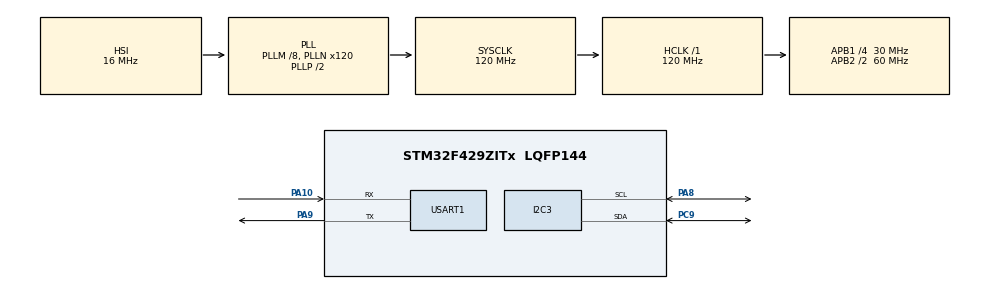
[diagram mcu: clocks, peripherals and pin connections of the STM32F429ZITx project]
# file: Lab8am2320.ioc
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Mcu.Family=STM32F4
Mcu.Name=STM32F429ZITx
Mcu.Package=LQFP144
NVIC.PriorityGroup=NVIC_PRIORITYGROUP_4
PA10.Mode=Asynchronous
PA10.Signal=USART1_RX
PA8.Mode=I2C
PA8.Signal=I2C3_SCL
PA9.Mode=Asynchronous
PA9.Signal=USART1_TX
PC9.Mode=I2C
PC9.Signal=I2C3_SDA
ProjectManager.HeapSize=0x200
ProjectManager.StackSize=0x400
ProjectManager.TargetToolchain=STM32CubeIDE
RCC.48MHZClocksFreq_Value=60000000
RCC.AHBFreq_Value=120000000
RCC.APB1CLKDivider=RCC_HCLK_DIV4
RCC.APB1Freq_Value=30000000
RCC.APB1TimFreq_Value=60000000
RCC.APB2CLKDivider=RCC_HCLK_DIV2
RCC.APB2Freq_Value=60000000
RCC.APB2TimFreq_Value=120000000
RCC.CortexFreq_Value=120000000
RCC.HCLKFreq_Value=120000000
RCC.HSE_VALUE=25000000
RCC.HSI_VALUE=16000000
RCC.LSE_VALUE=32768
RCC.PLLM=8
RCC.PLLN=120
RCC.SYSCLKFreq_VALUE=120000000
RCC.SYSCLKSource=RCC_SYSCLKSOURCE_PLLCLK
RCC.VCOOutputFreq_Value=240000000
USART1.VirtualMode=VM_ASYNC
board=custom

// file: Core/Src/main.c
/* USER CODE BEGIN Header */
/**
  ******************************************************************************
  * @file           : main.c
  * @brief          : Main program body
  ******************************************************************************
  * @attention
  *
  * <h2><center>&copy; Copyright (c) 2021 STMicroelectronics.
  * All rights reserved.</center></h2>
  *
  * This software component is licensed by ST under BSD 3-Clause license,
  * the "License"; You may not use this file except in compliance with the
  * License. You may obtain a copy of the License at:
  *                        opensource.org/licenses/BSD-3-Clause
  *
  ******************************************************************************
  */
/* USER CODE END Header */
#include "main.h"

/* USER CODE BEGIN Includes */
#include "am2320.h"
#include "string.h"
/* USER CODE END Includes */

I2C_HandleTypeDef hi2c3;

UART_HandleTypeDef huart1;

void SystemClock_Config(void);
static void MX_GPIO_Init(void);
static void MX_I2C3_Init(void);
static void MX_USART1_UART_Init(void);

int main(void)
{

  /* MCU Configuration--------------------------------------------------------*/

  /* Reset of all peripherals, Initializes the Flash interface and the Systick. */
  HAL_Init();

  /* Configure the system clock */
  SystemClock_Config();

  /* Initialize all configured peripherals */
  MX_GPIO_Init();
  MX_I2C3_Init();
  MX_USART1_UART_Init();
  /* USER CODE BEGIN 2 */
  Am2320_HandleTypeDef Am2320_;
  Am2320_ = am2320_Init(&hi2c3, 0x5C << 1);
  float temperature, humidity;
  char str[50];
  /* USER CODE END 2 */

  /* Infinite loop */
  while (1)
  {

    /* USER CODE BEGIN 3 */
	  am2320_GetTemperatureAndHumidity(&Am2320_, &temperature, &humidity);
	  uint8_t* sentTemp;
	  uint8_t sentHumid;
	  sprintf(str, "Temperature = %4.1f\tHumidity = %4.1f\n\r", temperature, humidity);
	  	  while(__HAL_UART_GET_FLAG(&huart1,UART_FLAG_TC)==RESET){}
	  	  HAL_UART_Transmit(&huart1, (uint8_t*) str, strlen(str), 200);
	    HAL_Delay(3000);
  }
  /* USER CODE END 3 */
}

void SystemClock_Config(void)
{
  RCC_OscInitTypeDef RCC_OscInitStruct = {0};
  RCC_ClkInitTypeDef RCC_ClkInitStruct = {0};

  /** Configure the main internal regulator output voltage
  */
  __HAL_RCC_PWR_CLK_ENABLE();
  __HAL_PWR_VOLTAGESCALING_CONFIG(PWR_REGULATOR_VOLTAGE_SCALE3);
  /** Initializes the RCC Oscillators according to the specified parameters
  * in the RCC_OscInitTypeDef structure.
  */
  RCC_OscInitStruct.OscillatorType = RCC_OSCILLATORTYPE_HSI;
  RCC_OscInitStruct.HSIState = RCC_HSI_ON;
  RCC_OscInitStruct.HSICalibrationValue = RCC_HSICALIBRATION_DEFAULT;
  RCC_OscInitStruct.PLL.PLLState = RCC_PLL_ON;
  RCC_OscInitStruct.PLL.PLLSource = RCC_PLLSOURCE_HSI;
  RCC_OscInitStruct.PLL.PLLM = 8;
  RCC_OscInitStruct.PLL.PLLN = 120;
  RCC_OscInitStruct.PLL.PLLP = RCC_PLLP_DIV2;
  RCC_OscInitStruct.PLL.PLLQ = 4;
  if (HAL_RCC_OscConfig(&RCC_OscInitStruct) != HAL_OK)
  {
    Error_Handler();
  }
  /** Initializes the CPU, AHB and APB buses clocks
  */
  RCC_ClkInitStruct.ClockType = RCC_CLOCKTYPE_HCLK|RCC_CLOCKTYPE_SYSCLK
                              |RCC_CLOCKTYPE_PCLK1|RCC_CLOCKTYPE_PCLK2;
  RCC_ClkInitStruct.SYSCLKSource = RCC_SYSCLKSOURCE_PLLCLK;
  RCC_ClkInitStruct.AHBCLKDivider = RCC_SYSCLK_DIV1;
  RCC_ClkInitStruct.APB1CLKDivider = RCC_HCLK_DIV4;
  RCC_ClkInitStruct.APB2CLKDivider = RCC_HCLK_DIV2;

  if (HAL_RCC_ClockConfig(&RCC_ClkInitStruct, FLASH_LATENCY_3) != HAL_OK)
  {
    Error_Handler();
  }
}

static void MX_I2C3_Init(void)
{

  hi2c3.Instance = I2C3;
  hi2c3.Init.ClockSpeed = 100000;
  hi2c3.Init.DutyCycle = I2C_DUTYCYCLE_2;
  hi2c3.Init.OwnAddress1 = 0;
  hi2c3.Init.AddressingMode = I2C_ADDRESSINGMODE_7BIT;
  hi2c3.Init.DualAddressMode = I2C_DUALADDRESS_DISABLE;
  hi2c3.Init.OwnAddress2 = 0;
  hi2c3.Init.GeneralCallMode = I2C_GENERALCALL_DISABLE;
  hi2c3.Init.NoStretchMode = I2C_NOSTRETCH_DISABLE;
  if (HAL_I2C_Init(&hi2c3) != HAL_OK)
  {
    Error_Handler();
  }
  /** Configure Analogue filter
  */
  if (HAL_I2CEx_ConfigAnalogFilter(&hi2c3, I2C_ANALOGFILTER_ENABLE) != HAL_OK)
  {
    Error_Handler();
  }
  /** Configure Digital filter
  */
  if (HAL_I2CEx_ConfigDigitalFilter(&hi2c3, 0) != HAL_OK)
  {
    Error_Handler();
  }

}

static void MX_USART1_UART_Init(void)
{

  huart1.Instance = USART1;
  huart1.Init.BaudRate = 115200;
  huart1.Init.WordLength = UART_WORDLENGTH_8B;
  huart1.Init.StopBits = UART_STOPBITS_1;
  huart1.Init.Parity = UART_PARITY_NONE;
  huart1.Init.Mode = UART_MODE_TX_RX;
  huart1.Init.HwFlowCtl = UART_HWCONTROL_NONE;
  huart1.Init.OverSampling = UART_OVERSAMPLING_16;
  if (HAL_UART_Init(&huart1) != HAL_OK)
  {
    Error_Handler();
  }

}

static void MX_GPIO_Init(void)
{

  /* GPIO Ports Clock Enable */
  __HAL_RCC_GPIOC_CLK_ENABLE();
  __HAL_RCC_GPIOA_CLK_ENABLE();

}

void Error_Handler(void)
{
  __disable_irq();
  while (1)
  {
  }
}

/************************ (C) COPYRIGHT STMicroelectronics *****END OF FILE****/
